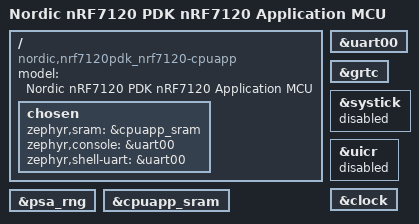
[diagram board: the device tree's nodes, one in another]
/*
 * Copyright (c) 2025 Nordic Semiconductor ASA
 *
 * SPDX-License-Identifier: LicenseRef-Nordic-5-Clause
 */

/dts-v1/;

#include "nrf7120_cpuapp_common.dtsi"
#include "nrf7120pdk_nrf7120-fpga-pinctrl.dtsi"

/ {
	compatible = "nordic,nrf7120pdk_nrf7120-cpuapp";
	model = "Nordic nRF7120 PDK nRF7120 Application MCU";

	chosen {
		zephyr,sram = &cpuapp_sram;
		zephyr,console = &uart00;
		zephyr,shell-uart = &uart00;
	};
};

&uart00 {
	status = "okay";
};

&grtc {
	status = "okay";
};

&systick {
	status = "disabled";
};

&psa_rng {
	status = "okay";
};

&uicr {
	status = "disabled";
};

&clock {
	status = "okay";
};

&cpuapp_sram {
	status = "okay";
};
